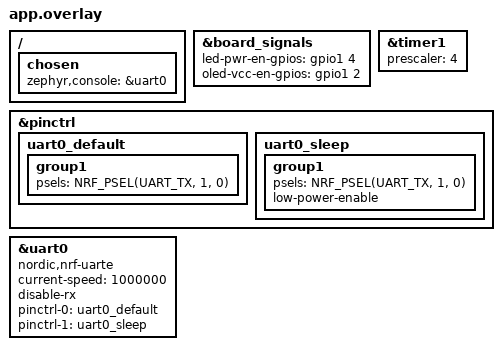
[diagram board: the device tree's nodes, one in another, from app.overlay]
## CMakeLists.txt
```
# SPDX-License-Identifier: Apache-2.0
# W1 firmware (Phase 2 plan section 2 W1, milestone W-fw; ADR-009 D6, Amendment 2): the POF
# blanking rule R8 of dial-me-spinner docs/firmware.md section 12.4 on the charging cue. A fixed
# BUILD_VERSION and no boot banner keep the workspace's `git describe` out of the image, so the
# image hash does not depend on the workspace.
cmake_minimum_required(VERSION 3.20.0)
set(BUILD_VERSION bb-dms-w1-cue-1)
# The out-of-tree board (../boards/dial/dial_me_spinner) and its bindings (../dts/bindings).
list(APPEND BOARD_ROOT ${CMAKE_CURRENT_LIST_DIR}/..)
list(APPEND DTS_ROOT ${CMAKE_CURRENT_LIST_DIR}/..)
find_package(Zephyr REQUIRED HINTS $ENV{ZEPHYR_BASE})
project(w1_cue)
target_sources(app PRIVATE src/main.c)
```

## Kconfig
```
# SPDX-License-Identifier: Apache-2.0
config W1_BLANK_MS
	int "POFWARN blanking after LED_PWR_EN rises (ms); 0: no blanking"
	default 10
	range 0 100
	help
	  The one switch between the four W1 images (Phase 2 milestone W-fw):
	  10 (w1_rule.elf: dial-me-spinner docs/firmware.md section 12.4's
	  rule, "ignores POFWARN for 10 ms after it raises LED_PWR_EN"),
	  4 (w1_blank4.elf: the window-midpoint negative control, the whole ms
	  nearest the midpoint of the stress corner's 2.94 V window, 3.255-4.089
	  ms after LED_PWR_EN; ADR-009 Amendment 2), 5 (w1_blank5.elf: the 5 ms
	  blanking the plan reports) and 0 (w1_blank_off.elf: POFCON stays
	  enabled through the edge, the second negative control).

config W1_CUE_DELAY_MS
	int "Delay from main() to the charging cue (LED_PWR_EN high) (ms)"
	default 1
	help
	  The boot steps before the cue that Phase 2 cannot run (the charger's
	  I2C setup), as one sleep.

config W1_DIN_DELAY_MS
	int "Delay from LED_PWR_EN high to P0.06 high, the cue's first frame (ms)"
	default 15
	help
	  At least 10 ms with P0.06 low after VLED is switched on
	  (firmware.md section 6.4, LED-DATA-V4), and clear of the 10 ms
	  blanking's end.

source "Kconfig.zephyr"
```

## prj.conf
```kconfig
# SPDX-License-Identifier: Apache-2.0
# GPIO, TIMER1 through the counter API (the blanking), POFCON through nrfx_power (its POFWARN
# handler runs from Zephyr's POWER_CLOCK interrupt), and printk on the UARTE0 console (the log
# lines of ADR-008 D8). No regulator framework: regulator_enable() sleeps off-on-delay-us inside
# the call (ADR-008 Amendment 3), and the blanking starts at the LED_PWR_EN edge. No logging
# subsystem and no boot banner (ADR-008 D5: no `git describe` in the image).
CONFIG_GPIO=y
CONFIG_COUNTER=y
CONFIG_NRFX_POWER=y
CONFIG_REGULATOR=n
CONFIG_BOOT_BANNER=n
CONFIG_SERIAL=y
CONFIG_CONSOLE=y
CONFIG_UART_CONSOLE=y
CONFIG_PRINTK=y
CONFIG_LOG=n
```

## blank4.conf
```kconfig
# w1_blank4.elf: the window-midpoint negative control (Kconfig W1_BLANK_MS; ADR-009 Amendment 2).
CONFIG_W1_BLANK_MS=4
```

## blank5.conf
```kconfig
# w1_blank5.elf: the 5 ms blanking the plan reports (Kconfig W1_BLANK_MS).
CONFIG_W1_BLANK_MS=5
```

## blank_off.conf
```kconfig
# w1_blank_off.elf: no blanking, the second negative control (Kconfig W1_BLANK_MS).
CONFIG_W1_BLANK_MS=0
```

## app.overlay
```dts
/*
 * SPDX-License-Identifier: Apache-2.0
 *
 * W1's additions to the board subset (Phase 2 milestone W-fw), transcribed from dial-me-spinner
 * docs/firmware.md section 3.1 (the board DTS draft) and section 1.3 (the pin table) at 6854d25:
 *   - board-signals: LED_PWR_EN (P1.04, U2's ON, R3 100 kOhm pull-down) and OLED_VCC_EN (P1.02,
 *     U21's ON, R25 100 kOhm pull-down) as plain GPIO outputs. The draft's VLED and OLED regulator
 *     nodes drive the same pins; the W1 firmware does not use the regulator framework (its
 *     regulator_enable() sleeps inside the call, ADR-008 Amendment 3), so the vled node is
 *     deleted here and P1.04 has one owner;
 *   - TIMER1 at 1 MHz (prescaler 4): the POFWARN blanking's timer;
 *   - UARTE0, TX only on P1.00 at 1 Mbaud, as the console (the log, ADR-008 D8).
 * An application overlay, not the board file, so the E1-E3 images build exactly as before.
 */
/delete-node/ &vled;

/ {
	chosen {
		zephyr,console = &uart0;               /* TX-only log on P1.00 */
	};
};

&board_signals {
	led-pwr-en-gpios = <&gpio1 4 GPIO_ACTIVE_HIGH>;    /* LED_PWR_EN -> U2 TPS22917 ON */
	oled-vcc-en-gpios = <&gpio1 2 GPIO_ACTIVE_HIGH>;   /* OLED_VCC_EN -> U21 TPS22917 ON */
};

&timer1 {
	status = "okay";
	prescaler = <4>;                       /* 16 MHz / 2^4 = 1 MHz */
};

&pinctrl {
	uart0_default: uart0_default {
		group1 {
			psels = <NRF_PSEL(UART_TX, 1, 0)>;
		};
	};
	uart0_sleep: uart0_sleep {
		group1 {
			psels = <NRF_PSEL(UART_TX, 1, 0)>;
			low-power-enable;
		};
	};
};

&uart0 {
	compatible = "nordic,nrf-uarte";
	status = "okay";
	current-speed = <1000000>;
	disable-rx;
	pinctrl-0 = <&uart0_default>;
	pinctrl-1 = <&uart0_sleep>;
	pinctrl-names = "default", "sleep";
};
```

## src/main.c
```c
/*
 * SPDX-License-Identifier: Apache-2.0
 *
 * W1 firmware (Phase 2 plan section 2 W1 and milestone W-fw; ADR-009 D6, Amendment 2, decision
 * D-W1): the POF blanking rule R8 of dial-me-spinner docs/firmware.md section 12.4 (at 6854d25)
 * on the charging cue of a dead battery on USB. The firmware's part of the case:
 *
 *   Boot:  LED_PWR_EN (P1.04), LED_DIN_MCU (P0.06) and OLED_VCC_EN (P1.02) are outputs driven low
 *          (firmware.md section 1.3's default column); POFCON = POF | THRESHOLD V28 with the
 *          POFWARN interrupt (nrfx_power). V28 (2.8 V) is the highest normal-voltage code: the
 *          nRF52840 has no 2.9 V code (ADR-009 Context, Q12), so firmware.md's 2.9 V cannot be set.
 *   Cue:   W1_CUE_DELAY_MS after main() starts: the blanking starts (POFCON.POF = 0 and the
 *          POFWARN interrupt off, nrfx_power_pof_disable()), then LED_PWR_EN rises (U2 TPS22917
 *          inrush: +3V3 dips), then the blanking timer starts. When it expires the firmware
 *          re-enables POFCON at V28 (nrfx_power_pof_enable()). The nRF52840 raises POFWARN at
 *          enable if VDD is already below the threshold (PS v1.1; ADR-009 D6), so a dip still in
 *          progress when the blanking ends sheds the cue: the W1 firmware's choice of how to
 *          implement R8 (plan section 2 W1), not a statement of firmware.md.
 *          W1_DIN_DELAY_MS after LED_PWR_EN, P0.06 rises: it stands in for the first frame of the
 *          cue (the I2S drives no pin in Renode), at least 10 ms after VLED is switched on
 *          (firmware.md section 6.4, LED-DATA-V4), as in E1's led_rail.
 *   POF:   POFWARN outside the blanking sheds the cue at once (firmware.md section 12.4: "LEDs
 *          off"), in the section 6.4 order: P0.06 low, then LED_PWR_EN low. The cue stays off.
 *          SHIP after 100 ms needs the charger's I2C, which Phase 2 does not model (plan
 *          section 3 Out), so it is not implemented.
 *
 * CONFIG_W1_BLANK_MS is the one switch between the four images (milestone W-fw): 10 (w1_rule.elf,
 * firmware.md's rule), 4 (w1_blank4.elf: the window-midpoint negative control, the whole ms
 * nearest the midpoint of the stress corner's measured 2.94 V window, 3.255-4.089 ms after
 * LED_PWR_EN, ADR-009 Amendment 2), 5 (w1_blank5.elf, the 5 ms report) and 0 (w1_blank_off.elf:
 * no blanking, POFCON stays enabled through the edge; the second negative control).
 *
 * The blanking is timed by TIMER1 at 1 MHz (Zephyr's counter API), started right after the
 * LED_PWR_EN write, so it ends W1_BLANK_MS plus a few microseconds after the edge. The system
 * timer (RTC1, 30.5 us ticks, one tick added to every relative timeout) would end a 4 ms
 * blanking 4.03-4.06 ms after the edge, within three lattice cells of the stress window's end.
 * TIMER1 runs only during the blanking.
 *
 * The console (UARTE0 TX on P1.00, the tap of ADR-008 D8) prints a boot line and one line per
 * POFWARN. ILIM and SYS_REG of the BQ25180 are the bench's: the firmware has no I2C (plan
 * section 2 W1, recorded deviation).
 */
#include <zephyr/kernel.h>
#include <zephyr/drivers/counter.h>
#include <zephyr/drivers/gpio.h>
#include <zephyr/irq.h>
#include <zephyr/sys/printk.h>
#include <nrfx_power.h>

#define BLANK_US ((uint32_t)CONFIG_W1_BLANK_MS * 1000U)

static const struct gpio_dt_spec led_pwr_en =
	GPIO_DT_SPEC_GET(DT_NODELABEL(board_signals), led_pwr_en_gpios);
static const struct gpio_dt_spec led_din =
	GPIO_DT_SPEC_GET(DT_NODELABEL(board_signals), led_din_gpios);
static const struct gpio_dt_spec oled_vcc_en =
	GPIO_DT_SPEC_GET(DT_NODELABEL(board_signals), oled_vcc_en_gpios);
static const struct device *const blank_timer = DEVICE_DT_GET(DT_NODELABEL(timer1));

static volatile bool cue_on;
static volatile uint32_t pofwarns;
static K_SEM_DEFINE(pof_sem, 0, 1);

/* POFWARN (the POWER_CLOCK interrupt, through nrfx_power): shed the cue. */
static void pofwarn(void)
{
	pofwarns++;
	if (cue_on) {
		(void)gpio_pin_set_dt(&led_din, 0);
		(void)gpio_pin_set_dt(&led_pwr_en, 0);
		cue_on = false;
	}
	k_sem_give(&pof_sem);
}

static const nrfx_power_pofwarn_config_t pof_config = {
	.handler = pofwarn,
	.thr = NRF_POWER_POFTHR_V28,
};

/* TIMER1 compare: the blanking ends; POFCON is enabled again at V28. */
static void blanking_end(const struct device *dev, uint8_t chan, uint32_t ticks, void *user_data)
{
	ARG_UNUSED(chan);
	ARG_UNUSED(ticks);
	ARG_UNUSED(user_data);
	nrfx_power_pof_enable(&pof_config);
	(void)counter_stop(dev);
}

static struct counter_alarm_cfg blank_alarm = {
	.callback = blanking_end,
	.flags = 0, /* relative to the counter when the alarm is set */
};

int main(void)
{
	if (!gpio_is_ready_dt(&led_pwr_en) || !gpio_is_ready_dt(&led_din) ||
	    !gpio_is_ready_dt(&oled_vcc_en) || !device_is_ready(blank_timer)) {
		return 0;
	}
	(void)gpio_pin_configure_dt(&led_pwr_en, GPIO_OUTPUT_INACTIVE);
	(void)gpio_pin_configure_dt(&led_din, GPIO_OUTPUT_INACTIVE);
	(void)gpio_pin_configure_dt(&oled_vcc_en, GPIO_OUTPUT_INACTIVE);

	nrfx_power_pof_init(&pof_config);
	nrfx_power_pof_enable(&pof_config);
	blank_alarm.ticks = counter_us_to_ticks(blank_timer, BLANK_US);
	printk("w1: boot pofcon=V28 blank=%u ms\n", (unsigned int)CONFIG_W1_BLANK_MS);

	k_msleep(CONFIG_W1_CUE_DELAY_MS);

	/* The charging cue: LED_PWR_EN rises with POFWARN blanked for W1_BLANK_MS. */
	if (BLANK_US > 0U) {
		nrfx_power_pof_disable();
	}
	cue_on = true;
	(void)gpio_pin_set_dt(&led_pwr_en, 1);
	if (BLANK_US > 0U) {
		(void)counter_start(blank_timer);
		(void)counter_set_channel_alarm(blank_timer, 0, &blank_alarm);
	}

	/* The first frame, at least 10 ms after VLED is switched on, unless the cue was shed. */
	k_msleep(CONFIG_W1_DIN_DELAY_MS);
	unsigned int key = irq_lock();

	if (cue_on) {
		(void)gpio_pin_set_dt(&led_din, 1);
	}
	irq_unlock(key);

	for (;;) {
		(void)k_sem_take(&pof_sem, K_FOREVER);
		printk("w1: pofwarn n=%u cue=%s\n", (unsigned int)pofwarns, cue_on ? "on" : "shed");
	}
	return 0;
}
```
